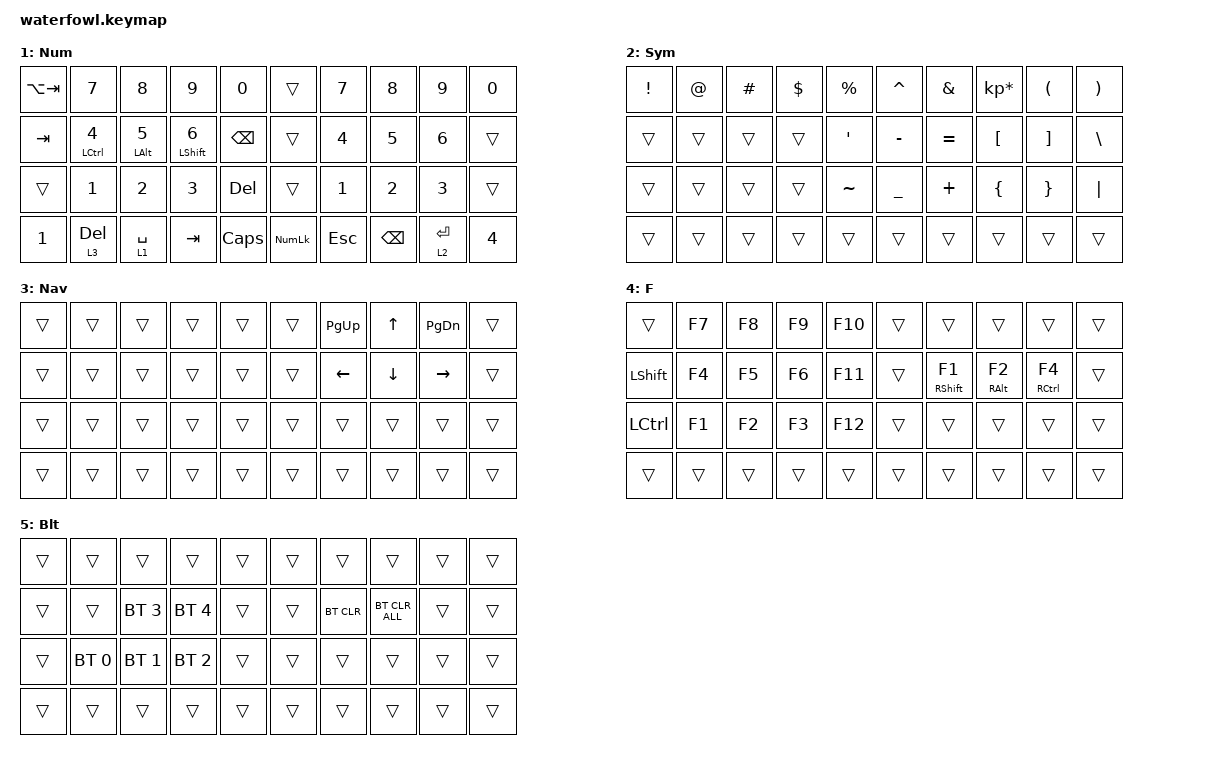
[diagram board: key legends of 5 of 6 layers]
/*
 * Copyright (c) 2022 The ZMK Contributors
 *
 * SPDX-License-Identifier: MIT
 */

#include <behaviors.dtsi>
#include <dt-bindings/zmk/keys.h>
#include <dt-bindings/zmk/bt.h>

&mt { flavor = "tap-preferred"; };

/ {
	keymap {
		compatible = "zmk,keymap";

		default_layer {
/* QWERTY
 *
 * ,----------------------------------.                      ,----------------------------------.
 * |   Q  |   W  |   E  |   R  |   T  |                      |   Y  |   U  |   I  |   O  |   P  |
 * |------+------+------+------+------|                      |------+------+------+------+------|
 * |   A  |   S  |   D  |   F  |   G  |                      |   H  |   J  |   K  |   L  |   ;  |
 * |------+------+------+------+------|  ,-----.    ,-----.  |------+------+------+------+------|
 * |   Z  |   X  |   C  |   V  |   B  |  |CAPS |    |NUMLK|  |   N  |   M  |   ,  |   .  |   /  |
 * `----------------------------------'  `-----'    `-----'  `----------------------------------'
 *          ,-----.   ,--------------------.            ,--------------------.   ,-----. 
 *          |  1  |   | DEL | SPACE | TAB  |            |  ESC  | BS | ENTER |   |  4  |	
 *          `-----'   `--------------------'            `--------------------'   `-----'
 */
			display-name = "Char";
			bindings = <
	&kp Q  &kp W               &kp E           &kp R             &kp T             &kp Y            &kp U              &kp I            &kp O                &mt BACKSPACE P 
&kp A     &mt LEFT_CONTROL S  &mt LEFT_ALT D  &mt LEFT_SHIFT F  &mt LEFT_GUI G    &mt RIGHT_GUI H  &mt RIGHT_SHIFT J  &mt RIGHT_ALT K  &mt RIGHT_CONTROL L  &lt 3 SEMI      
&kp Z         &kp X               &kp C           &kp V             &kp B             &kp N            &kp M              &kp COMMA        &kp DOT              &kp FSLH        
                                  &none           &lt 4 ESC         &lt 1 SPACE       &lt 2 ENTER      &lt 3 TAB          &none
     >;
 };

 number_layer {
     display-name = "Num";
     bindings = <
 &kp LA(TAB)  &kp N7              &kp NUMBER_8     &kp N9                   &kp N0           &trans  &kp N7        &kp N8        &kp N9        &kp N0
 &kp TAB      &mt LCTRL NUMBER_4  &mt LEFT_ALT N5  &mt LEFT_SHIFT NUMBER_6  &kp BACKSPACE    &trans  &kp NUMBER_4  &kp N5        &kp NUMBER_6  &trans
 &trans       &kp NUMBER_1        &kp NUMBER_2     &kp NUMBER_3             &kp DEL          &trans  &kp NUMBER_1  &kp NUMBER_2  &kp NUMBER_3  &trans
 &kp N1		  &lt 3 DEL			  &lt 1 SPACE	   &kp TAB					&kp CLCK		 &kp KP_NLCK	&kp ESC		&kp BSPC	&lt 2 RET	&kp N4
			>;

			sensor-bindings = <&inc_dec_kp PAGE_UP PAGE_DOWN &inc_dec_kp TAB LS(TAB)>;
 };

 symbol_layer {
     display-name = "Sym";
     bindings = <
 &kp EXCL  &kp AT  &kp HASH  &kp DLLR  &kp PRCNT    &kp CARET  &kp AMPS   &kp KP_MULTIPLY  &kp LPAR  &kp RPAR 
 &trans    &trans  &trans    &trans    &kp SQT      &kp MINUS  &kp EQUAL  &kp LBKT         &kp RBKT  &kp BSLH 
 &trans    &trans  &trans    &trans    &kp TILDE    &kp UNDER  &kp PLUS   &kp LBRC         &kp RBRC  &kp PIPE 
 &trans		  &trans		  &trans	   &trans					&trans		 &trans	&trans		&trans	&trans	&trans
			>;

			sensor-bindings = <&inc_dec_kp PAGE_UP PAGE_DOWN &inc_dec_kp TAB LS(TAB)>;
 };

 nav_layer {
     bindings = <
 &trans  &trans  &trans  &trans  &trans    &trans  &kp PAGE_UP  &kp UP    &kp PAGE_DOWN  &trans 
 &trans  &trans  &trans  &trans  &trans    &trans  &kp LEFT     &kp DOWN  &kp RIGHT      &trans 
 &trans  &trans  &trans  &trans  &trans    &trans  &trans       &trans    &trans         &trans 
 &trans		  &trans		  &trans	   &trans					&trans		 &trans	&trans		&trans	&trans	&trans
			>;

			sensor-bindings = <&inc_dec_kp PAGE_UP PAGE_DOWN &inc_dec_kp TAB LS(TAB)>;

     label = "Nav";
 };

 f-layer {
     bindings = <
 &trans     &kp F7  &kp F8  &kp F9  &kp F10    &trans  &trans              &trans            &trans        &trans 
 &kp LSHFT  &kp F4  &kp F5  &kp F6  &kp F11    &trans  &mt RIGHT_SHIFT F1  &mt RIGHT_ALT F2  &mt RCTRL F4  &trans 
 &kp LCTRL  &kp F1  &kp F2  &kp F3  &kp F12    &trans  &trans              &trans            &trans        &trans 
  &trans		  &trans		  &trans	   &trans					&trans		 &trans	&trans		&trans	&trans	&trans
			>;

			sensor-bindings = <&inc_dec_kp PAGE_UP PAGE_DOWN &inc_dec_kp TAB LS(TAB)>;
     label = "F";
 };

 Bluetooth {
     bindings = <
 &trans  &trans        &trans        &trans        &trans    &trans  &trans      &trans          &trans  &trans  
 &trans  &trans        &bt BT_SEL 3  &bt BT_SEL 4  &trans    &trans  &bt BT_CLR  &bt BT_CLR_ALL  &trans  &trans  
 &trans  &bt BT_SEL 0  &bt BT_SEL 1  &bt BT_SEL 2  &trans    &trans  &trans      &trans          &trans  &trans  
&trans		  &trans		  &trans	   &trans					&trans		 &trans	&trans		&trans	&trans	&trans
			>;

			sensor-bindings = <&inc_dec_kp PAGE_UP PAGE_DOWN &inc_dec_kp TAB LS(TAB)>;

            label = "Blt";
        };
    };
};
